AUTOSAR XML (schema 4-2-2)
package /Components
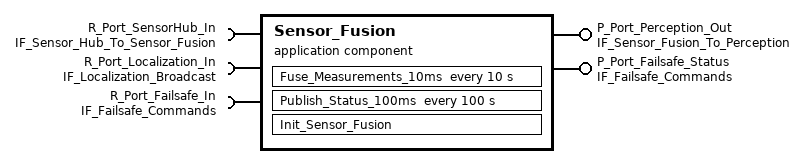
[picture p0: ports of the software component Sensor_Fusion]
  application sw component type Sensor_Fusion
    provide port P_Port_Perception_Out: provided-interface=IF_Sensor_Fusion_To_Perception
    provide port P_Port_Failsafe_Status: provided-interface=IF_Failsafe_Commands
    require port R_Port_SensorHub_In: required-interface=IF_Sensor_Hub_To_Sensor_Fusion
    require port R_Port_Localization_In: required-interface=IF_Localization_Broadcast
    require port R_Port_Failsafe_In: required-interface=IF_Failsafe_Commands
    behavior Sensor_Fusion_InternalBehavior
      init event Sensor_Fusion_Init: start-on-event=Init_Sensor_Fusion
      timing event Sensor_Fusion_10ms: start-on-event=Fuse_Measurements_10ms, period=10
      timing event Sensor_Fusion_100ms: start-on-event=Publish_Status_100ms, period=100
      runnable Init_Sensor_Fusion
        parameter access InitParamAccess_Localization_Status: accessed-parameter=R_Port_Localization_In.Localization_Status
      runnable Fuse_Measurements_10ms: minimum-start-interval=10
        data-receive-point-by-arguments:
          11 x access:
            Read_Camera_Frames: accessed-variable={autosar-variable-in-impl-datatype={port-prototype=R_Port_SensorHub_In, target-data-prototype=Camera_Frames_Impl}, autosar-variable=R_Port_SensorHub_In.Camera_Frames}
            Read_Radar_Detections: accessed-variable={autosar-variable-in-impl-datatype={port-prototype=R_Port_SensorHub_In, target-data-prototype=Radar_Detections_Impl}, autosar-variable=R_Port_SensorHub_In.Radar_Detections}
            Read_Ultrasonic_Detections: accessed-variable={autosar-variable-in-impl-datatype={port-prototype=R_Port_SensorHub_In, target-data-prototype=Ultrasonic_Detections_Impl}, autosar-variable=R_Port_SensorHub_In.Ultrasonic_Detections}
            Read_Lidar_PointCloud: accessed-variable={autosar-variable-in-impl-datatype={port-prototype=R_Port_SensorHub_In, target-data-prototype=Lidar_PointCloud_Impl}, autosar-variable=R_Port_SensorHub_In.Lidar_PointCloud}
            Read_IMU_Data: accessed-variable={autosar-variable-in-impl-datatype={port-prototype=R_Port_SensorHub_In, target-data-prototype=IMU_Data_Impl}, autosar-variable=R_Port_SensorHub_In.IMU_Data}
            Read_GNSS_Fix: accessed-variable={autosar-variable-in-impl-datatype={port-prototype=R_Port_SensorHub_In, target-data-prototype=GNSS_Fix_Impl}, autosar-variable=R_Port_SensorHub_In.GNSS_Fix}
            Read_Ego_Pose: accessed-variable={autosar-variable-in-impl-datatype={port-prototype=R_Port_Localization_In, target-data-prototype=Ego_Pose_Impl}, autosar-variable=R_Port_Localization_In.Ego_Pose}
            Read_Ego_Velocity: accessed-variable={autosar-variable-in-impl-datatype={port-prototype=R_Port_Localization_In, target-data-prototype=Ego_Velocity_Impl}, autosar-variable=R_Port_Localization_In.Ego_Velocity}
            Read_Localization_Status: accessed-variable={autosar-variable-in-impl-datatype={port-prototype=R_Port_Localization_In, target-data-prototype=Localization_Status_Impl}, autosar-variable=R_Port_Localization_In.Localization_Status}
            Read_MRC_Command: accessed-variable={autosar-variable-in-impl-datatype={port-prototype=R_Port_Failsafe_In, target-data-prototype=MRC_Command_Impl}, autosar-variable=R_Port_Failsafe_In.MRC_Command}
            Read_SOS_Command: accessed-variable={autosar-variable-in-impl-datatype={port-prototype=R_Port_Failsafe_In, target-data-prototype=SOS_Command_Impl}, autosar-variable=R_Port_Failsafe_In.SOS_Command}
        data-send-points:
          access Send_Fused_Object_List: accessed-variable={autosar-variable-in-impl-datatype={port-prototype=P_Port_Perception_Out, target-data-prototype=Fused_Object_List_Impl}, autosar-variable=P_Port_Perception_Out.Fused_Object_List}
          access Send_Occupancy_Grid: accessed-variable={autosar-variable-in-impl-datatype={port-prototype=P_Port_Perception_Out, target-data-prototype=Occupancy_Grid_Impl}, autosar-variable=P_Port_Perception_Out.Occupancy_Grid}
        data-write-access:
          access Write_Internal_Fusion_State: accessed-variable={autosar-variable-in-impl-datatype={port-prototype=P_Port_Perception_Out, target-data-prototype=Fusion_State_Impl}, autosar-variable=P_Port_Perception_Out.Fused_Object_List}
      runnable Publish_Status_100ms: minimum-start-interval=100
        data-send-points:
          access Send_Failsafe_Status: accessed-variable={autosar-variable-in-impl-datatype={port-prototype=P_Port_Failsafe_Status, target-data-prototype=Failsafe_Status_Impl}, autosar-variable=P_Port_Failsafe_Status.Failsafe_Status}
